# MKE15Z4 register map
Vendor: nxp.com; File version: 1.0
CPU: CM0PLUS r0p0, little endian, no MPU, no FPU, VTOR, 2 interrupt priority bits
Registers are 32-bit, read-write, reset 0x0 unless marked. A register's access mark holds for its fields unless they carry their own. Offsets are from the block's base; [hi:lo] are bit positions; {n}, {i} and the like mark numbered series.

## PMC
Base 0x4007D000; register names take the prefix PMC_
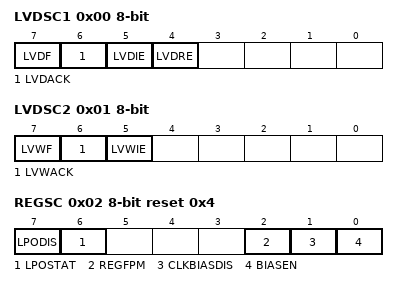
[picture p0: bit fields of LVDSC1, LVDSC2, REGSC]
0x00 LVDSC1 8-bit — Low Voltage Detect Status and Control 1 Register
  [7] LVDF ro — Low Voltage Detect Flag
    0=Low-voltage event not detected; 1=Low-voltage event detected
  [6] LVDACK wo — Low Voltage Detect Acknowledge
  [5] LVDIE — Low Voltage Detect Interrupt Enable
    0=Hardware interrupt disabled (use polling); 1=Request a hardware interrupt when LVDF = 1
  [4] LVDRE — Low Voltage Detect Reset Enable
    0=No system resets on low voltage detect events; 1=If the supply voltage falls below VLVD, a system reset will be generated
0x01 LVDSC2 8-bit — Low Voltage Detect Status and Control 2 Register
  [7] LVWF ro — Low-Voltage Warning Flag
    0=Low-voltage warning event not detected; 1=Low-voltage warning event detected
  [6] LVWACK wo — Low-Voltage Warning Acknowledge
  [5] LVWIE — Low-Voltage Warning Interrupt Enable
    0=Hardware interrupt disabled (use polling); 1=Request a hardware interrupt when LVWF=1
0x02 REGSC 8-bit reset 0x4 — Regulator Status and Control Register
  [7] LPODIS — LPO Disable Bit
    0=Low power oscillator enabled; 1=Low power oscillator disabled
  [6] LPOSTAT ro — LPO Status Bit
    0=Low power oscillator in low phase; 1=Low power oscillator in high phase
  [2] REGFPM ro — Regulator in Full Performance Mode Status Bit
    0=Regulator is in low power mode or transition to/from; 1=Regulator is in full performance mode
  [1] CLKBIASDIS — Clock Bias Disable Bit
    0=No effect; 1=In STOP or VLPS mode the bias currents and reference voltages for the following clock modules are disabled: SIRC, FIRC, PLL. (if available on device)
  [0] BIASEN — Bias Enable Bit
    0=Biasing disabled, core logic can run in full performance; 1=Biasing enabled, core logic is slower and there are restrictions in allowed system clock speed (see Data Sheet for details)
0x04 LPOTRIM 8-bit — Low Power Oscillator Trim Register
  [4:0] LPOTRIM — LPO trimming bits

## SMC — System Mode Controller
Base 0x4007E000; register names take the prefix SMC_
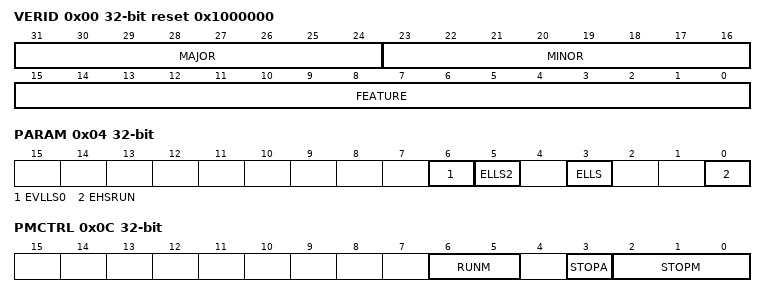
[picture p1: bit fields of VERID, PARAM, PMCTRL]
0x00 VERID ro reset 0x1000000 — SMC Version ID Register
  [31:24] MAJOR — Major Version Number
  [23:16] MINOR — Minor Version Number
  [15:0] FEATURE — Feature Specification Number
    0=Standard features implemented
0x04 PARAM ro — SMC Parameter Register
  [all] fields
    0=The feature is not available; 1=The feature is available
  [6] EVLLS0 — Existence of VLLS0 feature
  [5] ELLS2 — Existence of LLS2 feature
  [3] ELLS — Existence of LLS feature
  [0] EHSRUN — Existence of HSRUN feature
0x08 PMPROT — Power Mode Protection register
  [5] AVLP — Allow Very-Low-Power Modes
    0=VLPR, VLPW, and VLPS are not allowed; 1=VLPR, VLPW, and VLPS are allowed
0x0C PMCTRL — Power Mode Control register
  [6:5] RUNM — Run Mode Control
    0=Normal Run mode (RUN); 2=Very-Low-Power Run mode (VLPR)
  [3] STOPA ro — Stop Aborted
    0=The previous stop mode entry was successful; 1=The previous stop mode entry was aborted
  [2:0] STOPM — Stop Mode Control
    0=Normal Stop (STOP); 2=Very-Low-Power Stop (VLPS); 6=Reseved
0x10 STOPCTRL reset 0x3 — Stop Control Register
  [7:6] PSTOPO — Partial Stop Option
    0=STOP - Normal Stop mode; 1=PSTOP1 - Partial Stop with both system and bus clocks disabled; 2=PSTOP2 - Partial Stop with system clock disabled and bus clock enabled
0x14 PMSTAT ro reset 0x1 — Power Mode Status register
  [7:0] PMSTAT — Power Mode Status

## GPIOA — General Purpose Input/Output
Base 0x400FF000; register names take the prefix GPIOA_
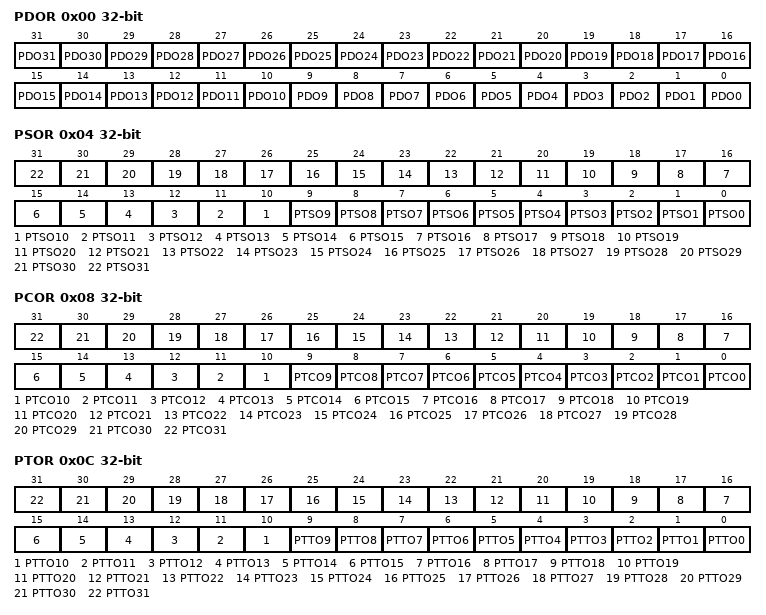
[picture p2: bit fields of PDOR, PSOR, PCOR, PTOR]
0x00 PDOR — Port Data Output Register
  [all] fields
    0=PDO_0 (Logic level 0 is driven on pin, provided pin is configured for general-purpose output.); 1=PDO_1 (Logic level 1 is driven on pin, provided pin is configured for general-purpose output.)
  [n] PDO{n} (n=0..31) — Port Data Output
0x04 PSOR — Port Set Output Register
  [all] fields
    0=PTSO_0 (Corresponding bit in PDORn does not change.); 1=PTSO_1 (Corresponding bit in PDORn is set to logic 1.)
  [n] PTSO{n} (n=0..31) — Port Set Output
0x08 PCOR — Port Clear Output Register
  [all] fields
    0=PTCO_0 (Corresponding bit in PDORn does not change.); 1=PTCO_1 (Corresponding bit in PDORn is cleared to logic 0.)
  [n] PTCO{n} (n=0..31) — Port Clear Output
0x0C PTOR — Port Toggle Output Register
  [all] fields
    0=PTTO_0 (Corresponding bit in PDORn does not change.); 1=PTTO_1 (Corresponding bit in PDORn is set to the inverse of its existing logic state.)
  [n] PTTO{n} (n=0..31) — Port Toggle Output
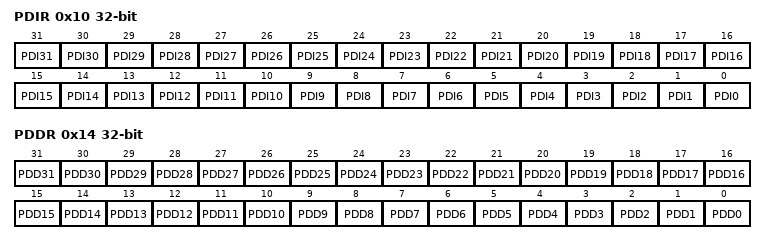
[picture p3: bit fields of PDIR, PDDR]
0x10 PDIR ro — Port Data Input Register
  [all] fields
    0=PDI_0 (Pin logic level is logic 0, or is not configured for use by digital function.); 1=PDI_1 (Pin logic level is logic 1.)
  [n] PDI{n} (n=0..31) — Port Data Input
0x14 PDDR — Port Data Direction Register
  [all] fields
    0=PDD_0 (Pin is configured as general-purpose input, for the GPIO function.); 1=PDD_1 (Pin is configured as general-purpose output, for the GPIO function.)
  [n] PDD{n} (n=0..31) — Port Data Direction

## GPIOB — General Purpose Input/Output
Base 0x400FF040; register names take the prefix GPIOB_
Registers as GPIOA.

## GPIOC — General Purpose Input/Output
Base 0x400FF080; register names take the prefix GPIOC_
Registers as GPIOA.

## GPIOD — General Purpose Input/Output
Base 0x400FF0C0; register names take the prefix GPIOD_
Registers as GPIOA.

## GPIOE — General Purpose Input/Output
Base 0x400FF100; register names take the prefix GPIOE_
Registers as GPIOA.
